# STM32G070xx register map
File version: 1.0
Registers are 32-bit, read-write, reset 0x0 unless marked. A register's access mark holds for its fields unless they carry their own. Offsets are from the block's base; [hi:lo] are bit positions; {n}, {i} and the like mark numbered series.

## PWR — Power Control
Base 0x40007000
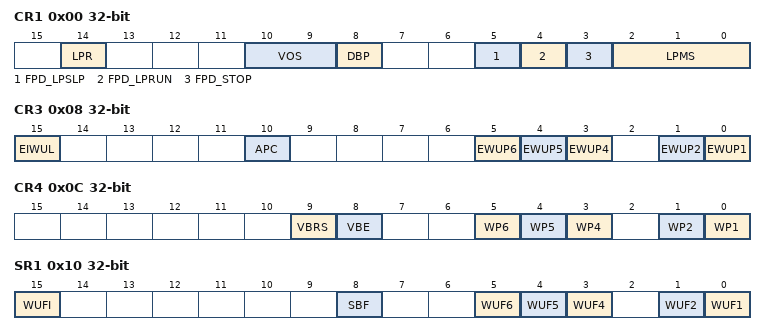
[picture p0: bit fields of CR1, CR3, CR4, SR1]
0x00 CR1 — PWR Power Control Register 1
  [14] LPR — Regulator Low-Power Run mode
  [10:9] VOS — Voltage scaling
    1=SCALE1; 2=SCALE2
  [8] DBP — Disable Backup Domain write protection
  [5] FPD_LPSLP — Flash power down mode during sleep
  [4] FPD_LPRUN — Flash power down mode during run
  [3] FPD_STOP — Flash power down mode during stop
  [2:0] LPMS — Low Power Mode Selection
    0=STOP0; 1=STOP1; 3=STANDBY
0x08 CR3 — PWR Power Control Register 3
  [15] EIWUL — Enable Internal Wake-up line
  [10] APC — Apply pull-up and pull-down configuration
  [5] EWUP6 — Enable WKUP pin 6
  [4] EWUP5 — Enable WKUP pin 5
  [3] EWUP4 — Enable WKUP pin 4
  [1] EWUP2 — Enable WKUP pin 2
  [0] EWUP1 — Enable WKUP pin 1
0x0C CR4 — PWR Power Control Register 4
  [9] VBRS — VBAT Battery charging Resistor Selection
    0=RESISTOR_5K; 1=RESISTOR_1_5K
  [8] VBE — VBAT Battery charging Enable
  [5] WP6 — Wake-Up Pin 6 polarity
  [4] WP5 — Wake-Up Pin 5 polarity
  [3] WP4 — Wake-Up Pin 4 polarity
  [1] WP2 — Wake-Up Pin 2 polarity
  [0] WP1 — Wake-Up Pin 1 polarity
0x10 SR1 — PWR Power Status Register 1
  [15] WUFI — Wakeup Flag Internal
  [8] SBF — Standby Flag
  [5] WUF6 — Wakeup Flag 6
  [4] WUF5 — Wakeup Flag 5
  [3] WUF4 — Wakeup Flag 4
  [1] WUF2 — Wakeup Flag 2
  [0] WUF1 — Wakeup Flag 1
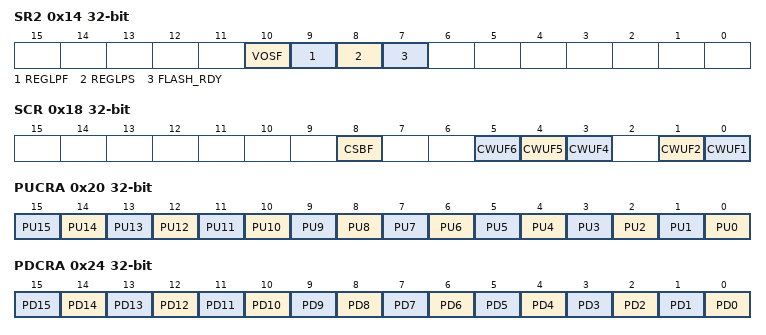
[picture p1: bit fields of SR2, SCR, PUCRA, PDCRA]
0x14 SR2 — PWR Power Status Register 2
  [10] VOSF — Voltage Scaling Flag
  [9] REGLPF — Regulator Low Power flag
  [8] REGLPS — Regulator Low Power started
  [7] FLASH_RDY — Flash Ready
0x18 SCR — PWR Power Status Clear Register
  [8] CSBF — Clear Standby Flag
  [5] CWUF6 — Clear Wake-up Flag 6
  [4] CWUF5 — Clear Wake-up Flag 5
  [3] CWUF4 — Clear Wake-up Flag 4
  [1] CWUF2 — Clear Wake-up Flag 2
  [0] CWUF1 — Clear Wake-up Flag 1
0x20 PUCRA — PWR Pull-Up Control Register of port A
  [n] PU{n} (n=0..15) — Pin PA{n} Pull-Up set
0x24 PDCRA — PWR Pull-Down Control Register of port A
  [n] PD{n} (n=0..15) — Pin PA{n} Pull-Down set
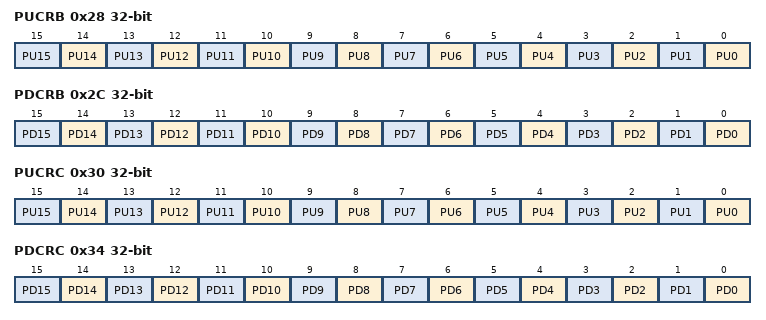
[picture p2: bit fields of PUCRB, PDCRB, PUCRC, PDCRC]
0x28 PUCRB — PWR Pull-Up Control Register of port B
  [n] PU{n} (n=0..15) — Pin PB{n} Pull-Up set
0x2C PDCRB — PWR Pull-Down Control Register of port B
  [n] PD{n} (n=0..15) — Pin PB{n} Pull-Down set
0x30 PUCRC — PWR Pull-Up Control Register of port C
  [n] PU{n} (n=0..15) — Pin PC{n} Pull-Up set
0x34 PDCRC — PWR Pull-Down Control Register of port C
  [n] PD{n} (n=0..15) — Pin PC{n} Pull-Down set
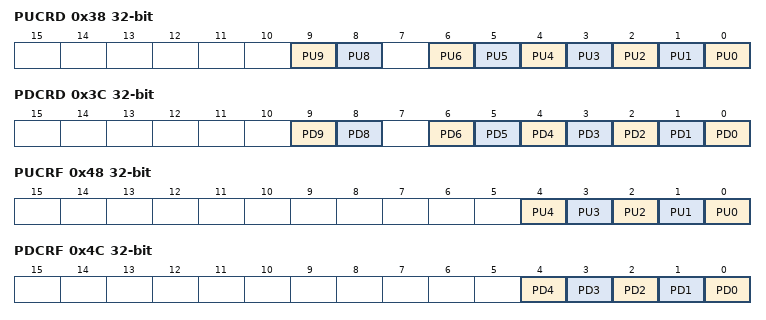
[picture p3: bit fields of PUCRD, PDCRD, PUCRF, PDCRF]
0x38 PUCRD — PWR Pull-Up Control Register of port D
  [9] PU9 — Pin PD9 Pull-Up set
  [8] PU8 — Pin PD8 Pull-Up set
  [n] PU{n} (n=0..6) — Pin PD{n} Pull-Up set
0x3C PDCRD — PWR Pull-Down Control Register of port D
  [9] PD9 — Pin PD9 Pull-Down set
  [8] PD8 — Pin PD8 Pull-Down set
  [n] PD{n} (n=0..6) — Pin PD{n} Pull-Down set
0x48 PUCRF — PWR Pull-Up Control Register of port F
  [n] PU{n} (n=0..4) — Pin PF{n} Pull-Up set
0x4C PDCRF — PWR Pull-Down Control Register of port F
  [n] PD{n} (n=0..4) — Pin PF{n} Pull-Down set

## TAMP — Tamper and backup registers
Base 0x4000B000
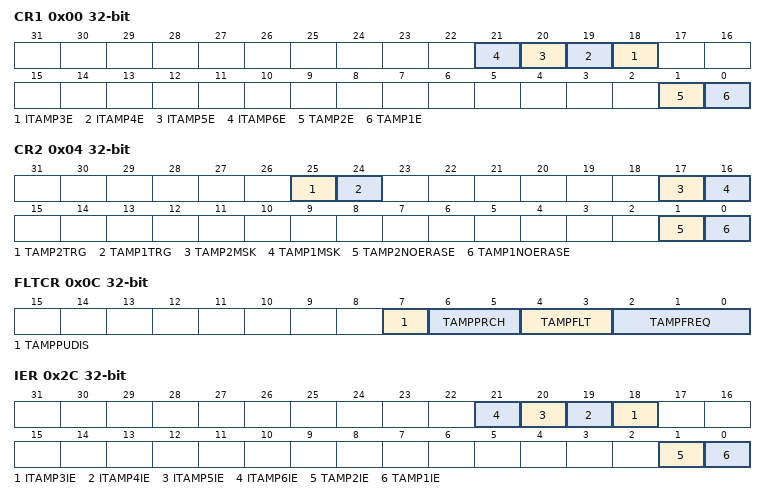
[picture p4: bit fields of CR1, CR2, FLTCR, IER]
0x00 CR1 — TAMP configuration register 1
  [n+15] ITAMP{n}E (n=3..6), [1] TAMP2E, [0] TAMP1E
0x04 CR2 — TAMP configuration register 2
  [25] TAMP2TRG, [24] TAMP1TRG, [17] TAMP2MSK, [16] TAMP1MSK, [1] TAMP2NOERASE, [0] TAMP1NOERASE
0x0C FLTCR — Reserved
  [7] TAMPPUDIS
  [6:5] TAMPPRCH
    0=DURATION_1RTCCLK (Tamper pins are pre-charged before sampling during 1 RTCCLK cycle); 1=DURATION_2RTCCLK (Tamper pins are pre-charged before sampling during 2 RTCCLK cycles); 2=DURATION_4RTCCLK (Tamper pins are pre-charged before sampling during 4 RTCCLK cycles); 3=DURATION_8RTCCLK (Tamper pins are pre-charged before sampling during 8 RTCCLK cycles)
  [4:3] TAMPFLT
    0=DISABLE (Tamper filter is disabled); 1=FILTER_2SAMPLE (Tamper is activated after 2 consecutive samples at the active level); 2=FILTER_4SAMPLE (Tamper is activated after 4 consecutive samples at the active level); 3=FILTER_8SAMPLE (Tamper is activated after 8 consecutive samples at the active level.)
  [2:0] TAMPFREQ
    0=SAMPLFREQDIV_32768 (Each of the tamper inputs are sampled with a frequency = RTCCLK / 32768); 1=SAMPLFREQDIV_16384 (Each of the tamper inputs are sampled with a frequency = RTCCLK / 16384); 2=SAMPLFREQDIV_8192 (Each of the tamper inputs are sampled with a frequency = RTCCLK / 8192); 3=SAMPLFREQDIV_4096 (Each of the tamper inputs are sampled with a frequency = RTCCLK / 4096); 4=SAMPLFREQDIV_2048 (Each of the tamper inputs are sampled with a frequency = RTCCLK / 2048); 5=SAMPLFREQDIV_1024 (Each of the tamper inputs are sampled with a frequency = RTCCLK / 1024); 6=SAMPLFREQDIV_512 (Each of the tamper inputs are sampled with a frequency = RTCCLK / 512); 7=SAMPLFREQDIV_256 (Each of the tamper inputs are sampled with a frequency = RTCCLK / 256)
0x2C IER — TAMP Interrupt enable register
  [n+15] ITAMP{n}IE (n=3..6), [1] TAMP2IE, [0] TAMP1IE
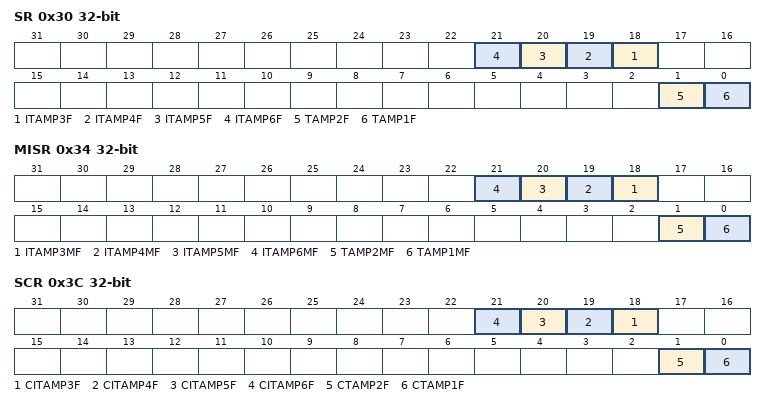
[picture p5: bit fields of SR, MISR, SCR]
0x30 SR — TAMP Status register
  [n+15] ITAMP{n}F (n=3..6), [1] TAMP2F, [0] TAMP1F
0x34 MISR — TAMP Masked Interrupt Status register
  [n+15] ITAMP{n}MF (n=3..6), [1] TAMP2MF, [0] TAMP1MF
0x3C SCR — TAMP Status clear register
  [n+15] CITAMP{n}F (n=3..6), [1] CTAMP2F, [0] CTAMP1F
{0x100+4i} BKP{i}R (i=0..4) — TAMP backup register {i}
